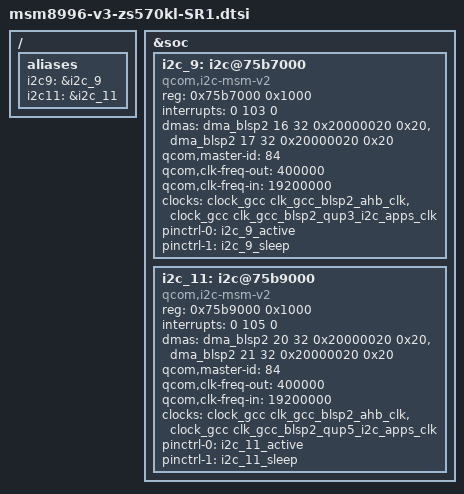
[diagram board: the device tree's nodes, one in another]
/* Copyright (c) 2014-2015, The Linux Foundation. All rights reserved.
 *
 * This program is free software; you can redistribute it and/or modify
 * it under the terms of the GNU General Public License version 2 and
 * only version 2 as published by the Free Software Foundation.
 *
 * This program is distributed in the hope that it will be useful,
 * but WITHOUT ANY WARRANTY; without even the implied warranty of
 * MERCHANTABILITY or FITNESS FOR A PARTICULAR PURPOSE.  See the
 * GNU General Public License for more details.
 */

/*
 * asus bsp rd add/overwrite bus or soc related node here
 */

#include "msm8996-v3.dtsi"

/ {
	aliases {
		i2c9 = &i2c_9;
		i2c11 = &i2c_11;
	};
};

&soc {
	i2c_9: i2c@75b7000 { /* BLSP2 QUP2 */
			compatible = "qcom,i2c-msm-v2";
			#address-cells = <1>;
			#size-cells = <0>;
			reg = < 0x75b7000   0x1000>;
			reg-names = "qup_phys_addr";
			interrupt-names = "qup_irq";
			interrupts = <0 103 0>;
			dmas = <&dma_blsp2 16 32 0x20000020 0x20>,
					<&dma_blsp2 17 32 0x20000020 0x20>;
			dma-names = "tx", "rx";
			qcom,master-id = <84>;
			qcom,clk-freq-out = <400000>;
			qcom,clk-freq-in  = <19200000>;
			clock-names = "iface_clk", "core_clk";
			clocks = <&clock_gcc clk_gcc_blsp2_ahb_clk>,
					 <&clock_gcc clk_gcc_blsp2_qup3_i2c_apps_clk>;
			pinctrl-names = "i2c_active", "i2c_sleep";
			pinctrl-0 = <&i2c_9_active>;
			pinctrl-1 = <&i2c_9_sleep>;
	};

    i2c_11: i2c@75b9000 { /* BLSP2 QUP2 */
            compatible = "qcom,i2c-msm-v2";
            #address-cells = <1>;
            #size-cells = <0>;
            reg = < 0x75b9000   0x1000>;
            reg-names = "qup_phys_addr";
            interrupt-names = "qup_irq";
            interrupts = <0 105 0>;
            dmas = <&dma_blsp2 20 32 0x20000020 0x20>,
                    <&dma_blsp2 21 32 0x20000020 0x20>;
            dma-names = "tx", "rx";
            qcom,master-id = <84>;
            qcom,clk-freq-out = <400000>;
            qcom,clk-freq-in  = <19200000>;
            clock-names = "iface_clk", "core_clk";
            clocks = <&clock_gcc clk_gcc_blsp2_ahb_clk>,
                     <&clock_gcc clk_gcc_blsp2_qup5_i2c_apps_clk>;
            pinctrl-names = "i2c_active", "i2c_sleep";
            pinctrl-0 = <&i2c_11_active>;
            pinctrl-1 = <&i2c_11_sleep>;
    };
};
